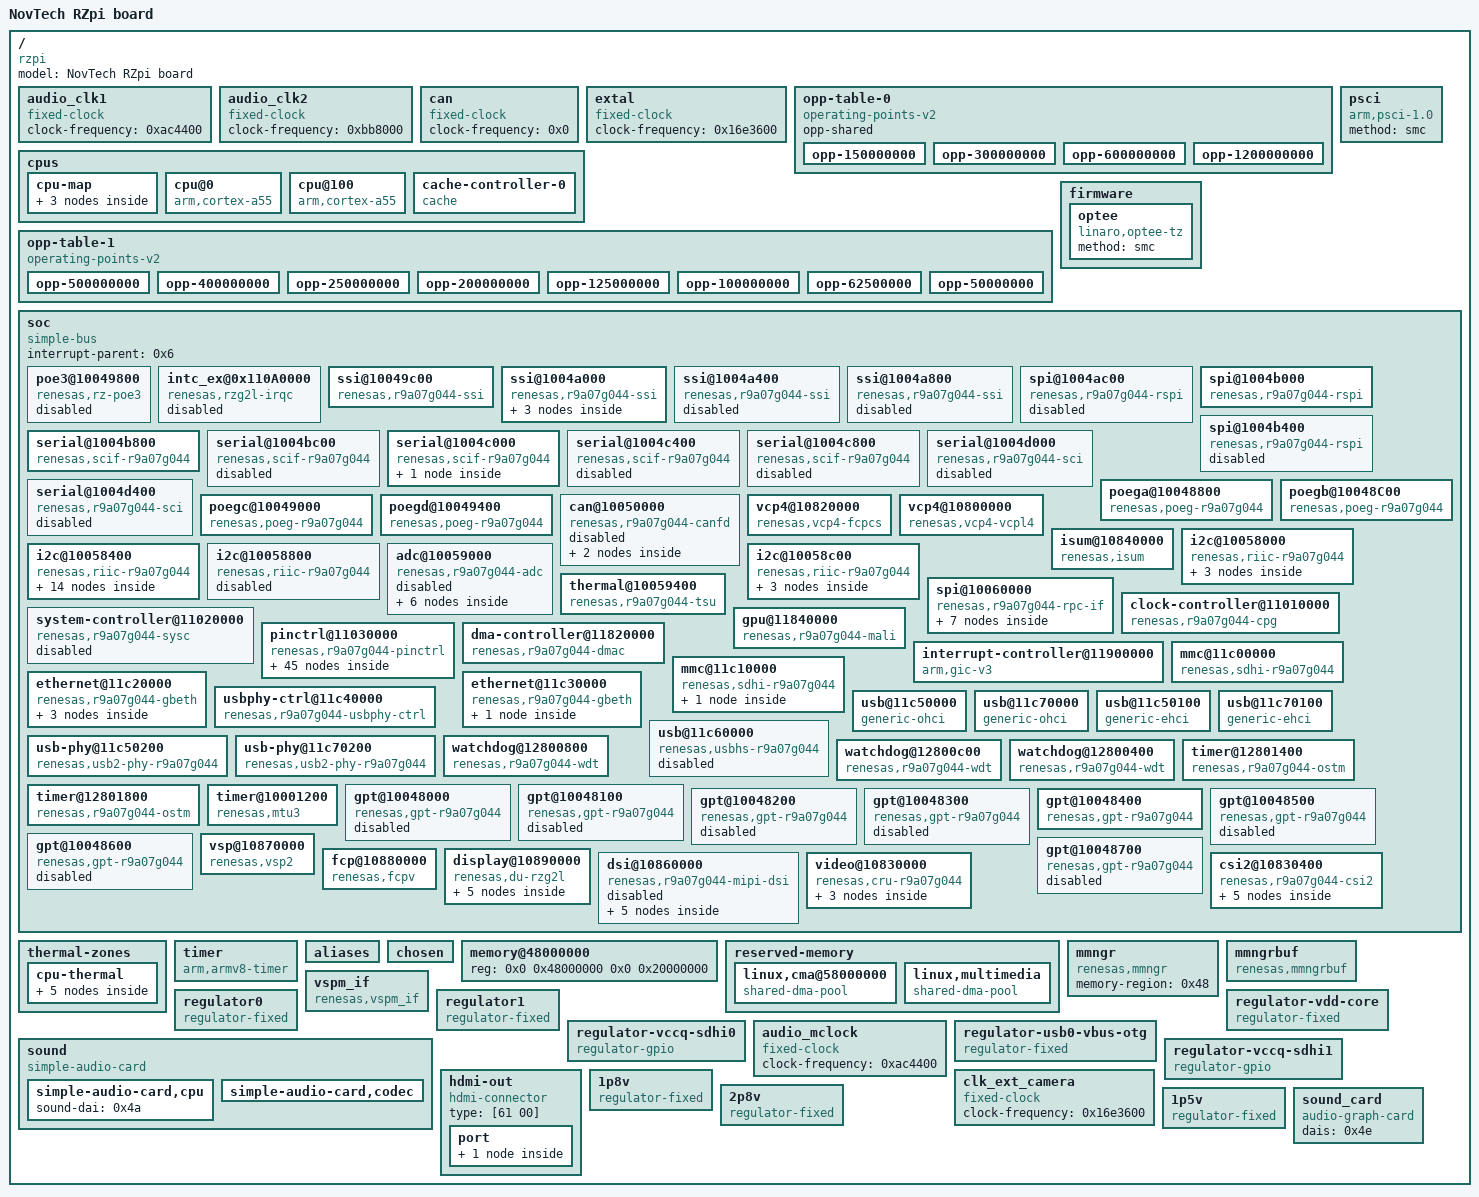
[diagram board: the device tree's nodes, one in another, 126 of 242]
/dts-v1/;

/ {
	compatible = "rzpi", "renesas,r9a07g044l2", "renesas,r9a07g044";
	#address-cells = <0x2>;
	#size-cells = <0x2>;
	model = "NovTech RZpi board";

	audio_clk1 {
		compatible = "fixed-clock";
		#clock-cells = <0x0>;
		clock-frequency = <0xac4400>;
		phandle = <0x7>;
	};

	audio_clk2 {
		compatible = "fixed-clock";
		#clock-cells = <0x0>;
		clock-frequency = <0xbb8000>;
		phandle = <0x8>;
	};

	can {
		compatible = "fixed-clock";
		#clock-cells = <0x0>;
		clock-frequency = <0x0>;
		phandle = <0x11>;
	};

	extal {
		compatible = "fixed-clock";
		#clock-cells = <0x0>;
		clock-frequency = <0x16e3600>;
		phandle = <0x24>;
	};

	opp-table-0 {
		compatible = "operating-points-v2";
		opp-shared;
		phandle = <0x5>;

		opp-150000000 {
			opp-hz = <0x0 0x8f0d180>;
			opp-microvolt = <0x10c8e0>;
			clock-latency-ns = <0x493e0>;
		};

		opp-300000000 {
			opp-hz = <0x0 0x11e1a300>;
			opp-microvolt = <0x10c8e0>;
			clock-latency-ns = <0x493e0>;
		};

		opp-600000000 {
			opp-hz = <0x0 0x23c34600>;
			opp-microvolt = <0x10c8e0>;
			clock-latency-ns = <0x493e0>;
		};

		opp-1200000000 {
			opp-hz = <0x0 0x47868c00>;
			opp-microvolt = <0x10c8e0>;
			clock-latency-ns = <0x493e0>;
			opp-suspend;
		};
	};

	cpus {
		#address-cells = <0x1>;
		#size-cells = <0x0>;

		cpu-map {

			cluster0 {

				core0 {
					cpu = <0x1>;
				};

				core1 {
					cpu = <0x2>;
				};
			};
		};

		cpu@0 {
			compatible = "arm,cortex-a55";
			reg = <0x0>;
			device_type = "cpu";
			#cooling-cells = <0x2>;
			next-level-cache = <0x3>;
			enable-method = "psci";
			clocks = <0x4 0x0 0x0>;
			operating-points-v2 = <0x5>;
			phandle = <0x1>;
		};

		cpu@100 {
			compatible = "arm,cortex-a55";
			reg = <0x100>;
			device_type = "cpu";
			next-level-cache = <0x3>;
			enable-method = "psci";
			clocks = <0x4 0x0 0x0>;
			operating-points-v2 = <0x5>;
			phandle = <0x2>;
		};

		cache-controller-0 {
			compatible = "cache";
			cache-unified;
			cache-size = <0x40000>;
			phandle = <0x3>;
		};
	};

	opp-table-1 {
		compatible = "operating-points-v2";
		phandle = <0x26>;

		opp-500000000 {
			opp-hz = <0x0 0x1dcd6500>;
			opp-microvolt = <0x10c8e0>;
		};

		opp-400000000 {
			opp-hz = <0x0 0x17d78400>;
			opp-microvolt = <0x10c8e0>;
		};

		opp-250000000 {
			opp-hz = <0x0 0xee6b280>;
			opp-microvolt = <0x10c8e0>;
		};

		opp-200000000 {
			opp-hz = <0x0 0xbebc200>;
			opp-microvolt = <0x10c8e0>;
		};

		opp-125000000 {
			opp-hz = <0x0 0x7735940>;
			opp-microvolt = <0x10c8e0>;
		};

		opp-100000000 {
			opp-hz = <0x0 0x5f5e100>;
			opp-microvolt = <0x10c8e0>;
		};

		opp-62500000 {
			opp-hz = <0x0 0x3b9aca0>;
			opp-microvolt = <0x10c8e0>;
		};

		opp-50000000 {
			opp-hz = <0x0 0x2faf080>;
			opp-microvolt = <0x10c8e0>;
		};
	};

	psci {
		compatible = "arm,psci-1.0", "arm,psci-0.2";
		method = "smc";
	};

	firmware {

		optee {
			compatible = "linaro,optee-tz";
			method = "smc";
		};
	};

	soc {
		compatible = "simple-bus";
		interrupt-parent = <0x6>;
		#address-cells = <0x2>;
		#size-cells = <0x2>;
		ranges;

		poe3@10049800 {
			compatible = "renesas,rz-poe3", "renesas,r9a07g044-poe3";
			reg = <0x0 0x10049800 0x0 0x18>;
			interrupts = <0x0 0xd6 0x4 0x0 0xd7 0x4 0x0 0xd8 0x4 0x0 0xd9 0x4>;
			interrupt-names = "oei1", "oei2", "oei3", "oei4";
			clocks = <0x4 0x1 0x12>;
			clock-names = "fck";
			resets = <0x4 0x18>;
			power-domains = <0x4>;
			status = "disabled";
		};

		intc_ex@0x110A0000 {
			compatible = "renesas,rzg2l-irqc";
			#interrupt-cells = <0x2>;
			interrupt-controller;
			reg = <0x0 0x110a0000 0x0 0x10000>;
			interrupts = <0x0 0x1 0x4 0x0 0x2 0x4 0x0 0x3 0x4 0x0 0x4 0x4 0x0 0x5 0x4 0x0 0x6 0x4 0x0 0x7 0x4 0x0 0x8 0x4 0x0 0x0 0x4>;
			interrupt-names = "irq0", "irq1", "irq2", "irq3", "irq4", "irq5", "irq6", "irq7", "nmi";
			clocks = <0x4 0x1 0x8>;
			resets = <0x4 0xf>;
			power-domains = <0x4>;
			status = "disabled";
		};

		ssi@10049c00 {
			compatible = "renesas,r9a07g044-ssi", "renesas,rz-ssi";
			reg = <0x0 0x10049c00 0x0 0x400>;
			interrupts = <0x0 0x146 0x4 0x0 0x147 0x1 0x0 0x148 0x1 0x0 0x149 0x1>;
			interrupt-names = "int_req", "dma_rx", "dma_tx", "dma_rt";
			clocks = <0x4 0x1 0x3c 0x4 0x1 0x3d 0x7 0x8>;
			clock-names = "ssi", "ssi_sfr", "audio_clk1", "audio_clk2";
			resets = <0x4 0x32>;
			dmas = <0x9 0x2655 0x9 0x2656>;
			dma-names = "tx", "rx";
			power-domains = <0x4>;
			#sound-dai-cells = <0x0>;
			status = "okay";
			pinctrl-0 = <0xa>;
			pinctrl-names = "default";
			phandle = <0x4a>;
		};

		ssi@1004a000 {
			compatible = "renesas,r9a07g044-ssi", "renesas,rz-ssi";
			reg = <0x0 0x1004a000 0x0 0x400>;
			interrupts = <0x0 0x14a 0x4 0x0 0x14b 0x1 0x0 0x14c 0x1 0x0 0x14d 0x1>;
			interrupt-names = "int_req", "dma_rx", "dma_tx", "dma_rt";
			clocks = <0x4 0x1 0x3e 0x4 0x1 0x3f 0x7 0x8>;
			clock-names = "ssi", "ssi_sfr", "audio_clk1", "audio_clk2";
			resets = <0x4 0x33>;
			dmas = <0x9 0x2659 0x9 0x265a>;
			dma-names = "tx", "rx";
			power-domains = <0x4>;
			#sound-dai-cells = <0x0>;
			status = "okay";
			pinctrl-0 = <0xb>;
			pinctrl-names = "default";

			ports {

				port@0 {
					phandle = <0x4e>;

					endpoint {
						remote-endpoint = <0xc>;
						dai-format = "i2s";
						phandle = <0x1f>;
					};
				};
			};
		};

		ssi@1004a400 {
			compatible = "renesas,r9a07g044-ssi", "renesas,rz-ssi";
			reg = <0x0 0x1004a400 0x0 0x400>;
			interrupts = <0x0 0x14e 0x4 0x0 0x14f 0x1 0x0 0x150 0x1 0x0 0x151 0x1>;
			interrupt-names = "int_req", "dma_rx", "dma_tx", "dma_rt";
			clocks = <0x4 0x1 0x40 0x4 0x1 0x41 0x7 0x8>;
			clock-names = "ssi", "ssi_sfr", "audio_clk1", "audio_clk2";
			resets = <0x4 0x34>;
			dmas = <0x9 0x265f>;
			dma-names = "rt";
			power-domains = <0x4>;
			#sound-dai-cells = <0x0>;
			status = "disabled";
		};

		ssi@1004a800 {
			compatible = "renesas,r9a07g044-ssi", "renesas,rz-ssi";
			reg = <0x0 0x1004a800 0x0 0x400>;
			interrupts = <0x0 0x152 0x4 0x0 0x153 0x1 0x0 0x154 0x1 0x0 0x155 0x1>;
			interrupt-names = "int_req", "dma_rx", "dma_tx", "dma_rt";
			clocks = <0x4 0x1 0x42 0x4 0x1 0x43 0x7 0x8>;
			clock-names = "ssi", "ssi_sfr", "audio_clk1", "audio_clk2";
			resets = <0x4 0x35>;
			dmas = <0x9 0x2661 0x9 0x2662>;
			dma-names = "tx", "rx";
			power-domains = <0x4>;
			#sound-dai-cells = <0x0>;
			status = "disabled";
		};

		spi@1004ac00 {
			compatible = "renesas,r9a07g044-rspi", "renesas,rspi-rz";
			reg = <0x0 0x1004ac00 0x0 0x400>;
			interrupts = <0x0 0x19f 0x4 0x0 0x19d 0x4 0x0 0x19e 0x4>;
			interrupt-names = "error", "rx", "tx";
			clocks = <0x4 0x1 0x59>;
			resets = <0x4 0x49>;
			power-domains = <0x4>;
			num-cs = <0x1>;
			#address-cells = <0x1>;
			#size-cells = <0x0>;
			status = "disabled";
		};

		spi@1004b000 {
			compatible = "renesas,r9a07g044-rspi", "renesas,rspi-rz";
			reg = <0x0 0x1004b000 0x0 0x400>;
			interrupts = <0x0 0x1a2 0x4 0x0 0x1a0 0x4 0x0 0x1a1 0x4>;
			interrupt-names = "error", "rx", "tx";
			clocks = <0x4 0x1 0x5a>;
			resets = <0x4 0x4a>;
			power-domains = <0x4>;
			num-cs = <0x1>;
			#address-cells = <0x1>;
			#size-cells = <0x0>;
			status = "okay";
			pinctrl-0 = <0xd>;
			pinctrl-names = "default";
			dmas = <0x9 0x2e99 0x9 0x2e9a>;
			dma-names = "tx", "rx";
		};

		spi@1004b400 {
			compatible = "renesas,r9a07g044-rspi", "renesas,rspi-rz";
			reg = <0x0 0x1004b400 0x0 0x400>;
			interrupts = <0x0 0x1a5 0x4 0x0 0x1a3 0x4 0x0 0x1a4 0x4>;
			interrupt-names = "error", "rx", "tx";
			clocks = <0x4 0x1 0x5b>;
			resets = <0x4 0x4b>;
			power-domains = <0x4>;
			num-cs = <0x1>;
			#address-cells = <0x1>;
			#size-cells = <0x0>;
			status = "disabled";
		};

		serial@1004b800 {
			compatible = "renesas,scif-r9a07g044";
			reg = <0x0 0x1004b800 0x0 0x400>;
			interrupts = <0x0 0x17c 0x4 0x0 0x17e 0x4 0x0 0x17f 0x4 0x0 0x17d 0x4 0x0 0x180 0x4 0x0 0x180 0x4>;
			interrupt-names = "eri", "rxi", "txi", "bri", "dri", "tei";
			clocks = <0x4 0x1 0x51>;
			clock-names = "fck";
			power-domains = <0x4>;
			resets = <0x4 0x41>;
			status = "okay";
			pinctrl-0 = <0xe>;
			pinctrl-names = "default";
		};

		serial@1004bc00 {
			compatible = "renesas,scif-r9a07g044";
			reg = <0x0 0x1004bc00 0x0 0x400>;
			interrupts = <0x0 0x181 0x4 0x0 0x183 0x4 0x0 0x184 0x4 0x0 0x182 0x4 0x0 0x185 0x4 0x0 0x185 0x4>;
			interrupt-names = "eri", "rxi", "txi", "bri", "dri", "tei";
			clocks = <0x4 0x1 0x52>;
			clock-names = "fck";
			power-domains = <0x4>;
			resets = <0x4 0x42>;
			status = "disabled";
		};

		serial@1004c000 {
			compatible = "renesas,scif-r9a07g044";
			reg = <0x0 0x1004c000 0x0 0x400>;
			interrupts = <0x0 0x186 0x4 0x0 0x188 0x4 0x0 0x189 0x4 0x0 0x187 0x4 0x0 0x18a 0x4 0x0 0x18a 0x4>;
			interrupt-names = "eri", "rxi", "txi", "bri", "dri", "tei";
			clocks = <0x4 0x1 0x53>;
			clock-names = "fck";
			power-domains = <0x4>;
			resets = <0x4 0x43>;
			status = "okay";
			pinctrl-names = "default";
			pinctrl-0 = <0xf>;
			uart-has-rtscts;

			bluetooth {
				compatible = "brcm,bcm43438-bt";
				device-wakeup-gpios = <0x10 0x128 0x1>;
				host-wakeup-gpios = <0x10 0x129 0x1>;
				status = "okay";
			};
		};

		serial@1004c400 {
			compatible = "renesas,scif-r9a07g044";
			reg = <0x0 0x1004c400 0x0 0x400>;
			interrupts = <0x0 0x18b 0x4 0x0 0x18d 0x4 0x0 0x18e 0x4 0x0 0x18c 0x4 0x0 0x18f 0x4 0x0 0x18f 0x4>;
			interrupt-names = "eri", "rxi", "txi", "bri", "dri", "tei";
			clocks = <0x4 0x1 0x54>;
			clock-names = "fck";
			power-domains = <0x4>;
			resets = <0x4 0x44>;
			status = "disabled";
		};

		serial@1004c800 {
			compatible = "renesas,scif-r9a07g044";
			reg = <0x0 0x1004c800 0x0 0x400>;
			interrupts = <0x0 0x190 0x4 0x0 0x192 0x4 0x0 0x193 0x4 0x0 0x191 0x4 0x0 0x194 0x4 0x0 0x194 0x4>;
			interrupt-names = "eri", "rxi", "txi", "bri", "dri", "tei";
			clocks = <0x4 0x1 0x55>;
			clock-names = "fck";
			power-domains = <0x4>;
			resets = <0x4 0x45>;
			status = "disabled";
		};

		serial@1004d000 {
			compatible = "renesas,r9a07g044-sci", "renesas,sci";
			reg = <0x0 0x1004d000 0x0 0x400>;
			interrupts = <0x0 0x195 0x4 0x0 0x196 0x4 0x0 0x197 0x4 0x0 0x198 0x4>;
			interrupt-names = "eri", "rxi", "txi", "tei";
			clocks = <0x4 0x1 0x56>;
			clock-names = "fck";
			power-domains = <0x4>;
			resets = <0x4 0x46>;
			status = "disabled";
		};

		serial@1004d400 {
			compatible = "renesas,r9a07g044-sci", "renesas,sci";
			reg = <0x0 0x1004d400 0x0 0x400>;
			interrupts = <0x0 0x199 0x4 0x0 0x19a 0x4 0x0 0x19b 0x4 0x0 0x19c 0x4>;
			interrupt-names = "eri", "rxi", "txi", "tei";
			clocks = <0x4 0x1 0x57>;
			clock-names = "fck";
			power-domains = <0x4>;
			resets = <0x4 0x47>;
			status = "disabled";
		};

		poega@10048800 {
			compatible = "renesas,poeg-r9a07g044";
			reg = <0x0 0x10048800 0x0 0x4>;
			interrupts = <0x0 0x142 0x4>;
			clocks = <0x4 0x1 0x14>;
			power-domains = <0x4>;
			resets = <0x4 0x1a>;
			status = "okay";
			phandle = <0x38>;
		};

		poegb@10048C00 {
			compatible = "renesas,poeg-r9a07g044";
			reg = <0x0 0x10048c00 0x0 0x4>;
			interrupts = <0x0 0x143 0x4>;
			clocks = <0x4 0x1 0x15>;
			power-domains = <0x4>;
			resets = <0x4 0x1b>;
			status = "okay";
			phandle = <0x39>;
		};

		poegc@10049000 {
			compatible = "renesas,poeg-r9a07g044";
			reg = <0x0 0x10049000 0x0 0x4>;
			interrupts = <0x0 0x144 0x4>;
			clocks = <0x4 0x1 0x16>;
			power-domains = <0x4>;
			resets = <0x4 0x1c>;
			status = "okay";
			phandle = <0x3a>;
		};

		poegd@10049400 {
			compatible = "renesas,poeg-r9a07g044";
			reg = <0x0 0x10049400 0x0 0x4>;
			interrupts = <0x0 0x145 0x4>;
			clocks = <0x4 0x1 0x17>;
			power-domains = <0x4>;
			resets = <0x4 0x1d>;
			status = "okay";
			phandle = <0x3b>;
		};

		can@10050000 {
			compatible = "renesas,r9a07g044-canfd", "renesas,rzg2l-canfd";
			reg = <0x0 0x10050000 0x0 0x8000>;
			interrupts = <0x0 0x1aa 0x4 0x0 0x1ab 0x4 0x0 0x1a6 0x4 0x0 0x1a8 0x4 0x0 0x1ac 0x4 0x0 0x1a7 0x4 0x0 0x1a9 0x4 0x0 0x1ad 0x4>;
			interrupt-names = "g_err", "g_recc", "ch0_err", "ch0_rec", "ch0_trx", "ch1_err", "ch1_rec", "ch1_trx";
			clocks = <0x4 0x1 0x5c 0x4 0x0 0x16 0x11>;
			clock-names = "fck", "canfd", "can_clk";
			assigned-clocks = <0x4 0x0 0x16>;
			assigned-clock-rates = <0x2faf080>;
			resets = <0x4 0x4c 0x4 0x4d>;
			reset-names = "rstp_n", "rstc_n";
			power-domains = <0x4>;
			status = "disabled";
			pinctrl-0 = <0x12 0x13>;
			pinctrl-names = "default";

			channel0 {
				status = "okay";
			};

			channel1 {
				status = "okay";
			};
		};

		vcp4@10820000 {
			compatible = "renesas,vcp4-fcpcs";
			reg = <0x0 0x10820000 0x0 0x200>;
			renesas,#ch = <0x0>;
		};

		vcp4@10800000 {
			compatible = "renesas,vcp4-vcpl4";
			reg = <0x0 0x10800000 0x0 0x200 0x0 0x10810200 0x0 0x200>;
			interrupts = <0x0 0xa1 0x4 0x0 0xa2 0x4>;
			clocks = <0x4 0x1 0x2d 0x4 0x1 0x2e>;
			power-domains = <0x4>;
			resets = <0x4 0x29 0x4 0x2a>;
			renesas,#ch = <0x0>;
			renesas,#fcp_ch = <0x0>;
		};

		isum@10840000 {
			compatible = "renesas,isum";
			reg = <0x0 0x10840000 0x0 0x1f4>;
			interrupts = <0x0 0x9d 0x4 0x0 0x9e 0x4 0x0 0x9f 0x4 0x0 0xa0 0x4>;
			clocks = <0x4 0x1 0x2b 0x4 0x1 0x2c>;
			clock-names = "isu_aclk", "isu_pclk";
			resets = <0x4 0x27 0x4 0x28>;
			reset-names = "aresetn", "presetn";
			renesas,#ch = <0x0>;
			renesas,#rpf = <0x1>;
			renesas,#wpf = <0x1>;
			renesas,has-rs;
			power-domains = <0x4>;
		};

		i2c@10058000 {
			#address-cells = <0x1>;
			#size-cells = <0x0>;
			compatible = "renesas,riic-r9a07g044", "renesas,riic-rz";
			reg = <0x0 0x10058000 0x0 0x400>;
			interrupts = <0x0 0x15e 0x4 0x0 0x15c 0x1 0x0 0x15d 0x1 0x0 0x160 0x4 0x0 0x161 0x4 0x0 0x15f 0x4 0x0 0x162 0x4 0x0 0x163 0x4>;
			interrupt-names = "tei", "ri", "ti", "spi", "sti", "naki", "ali", "tmoi";
			clocks = <0x4 0x1 0x4d>;
			clock-frequency = <0x186a0>;
			resets = <0x4 0x3d>;
			power-domains = <0x4>;
			status = "okay";
			pinctrl-0 = <0x14>;
			pinctrl-names = "default";

			camera@3c {
				compatible = "ovti,ov5645";
				reg = <0x3c>;
				clock-names = "xclk";
				clocks = <0x15>;
				clock-frequency = <0x16e3600>;
				vdddo-supply = <0x16>;
				vdda-supply = <0x17>;
				vddd-supply = <0x18>;
				enable-gpios = <0x10 0x10 0x0>;
				reset-gpios = <0x10 0x142 0x1>;

				port {

					endpoint {
						clock-lanes = <0x0>;
						data-lanes = <0x1 0x2>;
						remote-endpoint = <0x19>;
						phandle = <0x45>;
					};
				};
			};
		};

		i2c@10058400 {
			#address-cells = <0x1>;
			#size-cells = <0x0>;
			compatible = "renesas,riic-r9a07g044", "renesas,riic-rz";
			reg = <0x0 0x10058400 0x0 0x400>;
			interrupts = <0x0 0x166 0x4 0x0 0x164 0x1 0x0 0x165 0x1 0x0 0x168 0x4 0x0 0x169 0x4 0x0 0x167 0x4 0x0 0x16a 0x4 0x0 0x16b 0x4>;
			interrupt-names = "tei", "ri", "ti", "spi", "sti", "naki", "ali", "tmoi";
			clocks = <0x4 0x1 0x4e>;
			clock-frequency = <0x186a0>;
			resets = <0x4 0x3e>;
			power-domains = <0x4>;
			status = "okay";
			pinctrl-0 = <0x1a>;
			pinctrl-names = "default";

			hdmi@3d {
				compatible = "adi,adv7535";
				reg = <0x3d>;
				avdd-supply = <0x1b>;
				dvdd-supply = <0x1b>;
				pvdd-supply = <0x1b>;
				a2vdd-supply = <0x1b>;
				v3p3-supply = <0x1c>;
				v1p2-supply = <0x1b>;
				adi,dsi-lanes = <0x4>;
				#sound-dai-cells = <0x0>;
				interrupt-parent = <0x10>;
				interrupts = <0x11 0x2>;
				status = "disabled";

				ports {
					#address-cells = <0x1>;
					#size-cells = <0x0>;

					port@0 {
						reg = <0x0>;

						endpoint@0 {
							remote-endpoint = <0x1d>;
							phandle = <0x42>;
						};
					};

					port@1 {
						reg = <0x1>;

						endpoint@1 {
							remote-endpoint = <0x1e>;
						};
					};

					port@2 {
						reg = <0x2>;

						endpoint {
							remote-endpoint = <0x1f>;
							phandle = <0xc>;
						};
					};
				};
			};

			hdmi@39 {
				#sound-dai-cells = <0x0>;
				compatible = "sil,sii9022";
				reg = <0x39>;
				status = "okay";

				ports {
					#address-cells = <0x1>;
					#size-cells = <0x0>;

					port@0 {
						reg = <0x0>;

						endpoint {
							remote-endpoint = <0x20>;
							phandle = <0x3f>;
						};
					};

					port@1 {
						reg = <0x1>;

						endpoint {
							remote-endpoint = <0x1e>;
							phandle = <0x4d>;
						};
					};
				};
			};
		};

		i2c@10058800 {
			#address-cells = <0x1>;
			#size-cells = <0x0>;
			compatible = "renesas,riic-r9a07g044", "renesas,riic-rz";
			reg = <0x0 0x10058800 0x0 0x400>;
			interrupts = <0x0 0x16e 0x4 0x0 0x16c 0x1 0x0 0x16d 0x1 0x0 0x170 0x4 0x0 0x171 0x4 0x0 0x16f 0x4 0x0 0x172 0x4 0x0 0x173 0x4>;
			interrupt-names = "tei", "ri", "ti", "spi", "sti", "naki", "ali", "tmoi";
			clocks = <0x4 0x1 0x4f>;
			clock-frequency = <0x186a0>;
			resets = <0x4 0x3f>;
			power-domains = <0x4>;
			status = "disabled";
		};

		i2c@10058c00 {
			#address-cells = <0x1>;
			#size-cells = <0x0>;
			compatible = "renesas,riic-r9a07g044", "renesas,riic-rz";
			reg = <0x0 0x10058c00 0x0 0x400>;
			interrupts = <0x0 0x176 0x4 0x0 0x174 0x1 0x0 0x175 0x1 0x0 0x178 0x4 0x0 0x179 0x4 0x0 0x177 0x4 0x0 0x17a 0x4 0x0 0x17b 0x4>;
			interrupt-names = "tei", "ri", "ti", "spi", "sti", "naki", "ali", "tmoi";
			clocks = <0x4 0x1 0x50>;
			clock-frequency = <0x61a80>;
			resets = <0x4 0x40>;
			power-domains = <0x4>;
			status = "okay";
			pinctrl-0 = <0x21>;
			pinctrl-names = "default";

			raa215300@12 {
				compatible = "renesas,raa215300";
				reg = <0x12>;
				rtc-enable;
			};

			isl1208@6f {
				compatible = "isil,isl1208";
				reg = <0x6f>;
				external-oscillator;
			};

			codec@1a {
				compatible = "wlf,wm8978";
				#sound-dai-cells = <0x0>;
				reg = <0x1a>;
				phandle = <0x4c>;
			};
		};

		adc@10059000 {
			compatible = "renesas,r9a07g044-adc", "renesas,rzg2l-adc";
			reg = <0x0 0x10059000 0x0 0x400>;
			interrupts = <0x0 0x15b 0x1>;
			clocks = <0x4 0x1 0x5e 0x4 0x1 0x5f>;
			clock-names = "adclk", "pclk";
			resets = <0x4 0x51 0x4 0x52>;
			reset-names = "presetn", "adrst-n";
			power-domains = <0x4>;
			status = "disabled";
			#address-cells = <0x1>;
			#size-cells = <0x0>;
			pinctrl-0 = <0x22>;
			pinctrl-names = "default";

			channel@0 {
				reg = <0x0>;
			};

			channel@1 {
				reg = <0x1>;
			};

			channel@2 {
				reg = <0x2>;
			};

			channel@3 {
				reg = <0x3>;
			};

			channel@4 {
				reg = <0x4>;
			};

			channel@5 {
				reg = <0x5>;
			};
		};

		thermal@10059400 {
			compatible = "renesas,r9a07g044-tsu", "renesas,rzg2l-tsu";
			reg = <0x0 0x10059400 0x0 0x400>;
			clocks = <0x4 0x1 0x60>;
			resets = <0x4 0x53>;
			power-domains = <0x4>;
			#thermal-sensor-cells = <0x1>;
			phandle = <0x46>;
		};

		spi@10060000 {
			compatible = "renesas,r9a07g044-rpc-if", "renesas,rzg2l-rpc-if";
			reg = <0x0 0x10060000 0x0 0x10000 0x0 0x20000000 0x0 0x10000000 0x0 0x10070000 0x0 0x10000>;
			reg-names = "regs", "dirmap", "wbuf";
			interrupts = <0x0 0x29 0x4>;
			clocks = <0x4 0x1 0x1e 0x4 0x1 0x1f>;
			resets = <0x4 0x21>;
			power-domains = <0x4>;
			#address-cells = <0x1>;
			#size-cells = <0x0>;
			status = "okay";
			pinctrl-0 = <0x23>;
			pinctrl-names = "default";

			flash@0 {
				compatible = "micron,mt25qu512a", "jedec,spi-nor";
				reg = <0x0>;
				m25p,fast-read;
				spi-max-frequency = <0x2faf080>;
				spi-rx-bus-width = <0x4>;
				spi-tx-bus-width = <0x4>;

				partitions {
					compatible = "fixed-partitions";
					#address-cells = <0x1>;
					#size-cells = <0x1>;

					partition@0000000 {
						label = "u-boot";
						reg = <0x0 0x80000>;
						read-only;
					};

					partition@80000 {
						label = "env";
						reg = <0x80000 0x40000>;
						read-only;
					};

					partition@C0000 {
						label = "dtb";
						reg = <0xc0000 0x40000>;
						read-only;
					};

					partition@800000 {
						label = "rootfs";
						reg = <0x800000 0x1000000>;
					};

					partition@2000000 {
						label = "test-area";
						reg = <0x2000000 0x100000>;
					};
				};
			};
		};

		clock-controller@11010000 {
			compatible = "renesas,r9a07g044-cpg";
			reg = <0x0 0x11010000 0x0 0x10000>;
			clocks = <0x24>;
			clock-names = "extal";
			#clock-cells = <0x2>;
			#reset-cells = <0x1>;
			#power-domain-cells = <0x0>;
			phandle = <0x4>;
		};

		system-controller@11020000 {
			compatible = "renesas,r9a07g044-sysc";
			reg = <0x0 0x11020000 0x0 0x10000>;
			interrupts = <0x0 0x2a 0x4 0x0 0x2b 0x4 0x0 0x2c 0x4 0x0 0x2d 0x4>;
			interrupt-names = "lpm_int", "ca55stbydone_int", "cm33stbyr_int", "ca55_deny";
			status = "disabled";
		};

		pinctrl@11030000 {
			compatible = "renesas,r9a07g044-pinctrl";
			reg = <0x0 0x11030000 0x0 0x10000 0x0 0x110a0020 0x0 0x30>;
			gpio-controller;
			#gpio-cells = <0x2>;
			gpio-ranges = <0x10 0x0 0x0 0x188>;
			clocks = <0x4 0x1 0x5d>;
			power-domains = <0x4>;
			resets = <0x4 0x4e 0x4 0x4f 0x4 0x50>;
			interrupt-controller;
			#interrupt-cells = <0x2>;
			interrupts = <0x0 0x1bc 0x4 0x0 0x1bd 0x4 0x0 0x1be 0x4 0x0 0x1bf 0x4 0x0 0x1c0 0x4 0x0 0x1c1 0x4 0x0 0x1c2 0x4 0x0 0x1c3 0x4 0x0 0x1c4 0x4 0x0 0x1c5 0x4 0x0 0x1c6 0x4 0x0 0x1c7 0x4 0x0 0x1c8 0x4 0x0 0x1c9 0x4 0x0 0x1ca 0x4 0x0 0x1cb 0x4 0x0 0x1cc 0x4 0x0 0x1cd 0x4 0x0 0x1ce 0x4 0x0 0x1cf 0x4 0x0 0x1d0 0x4 0x0 0x1d1 0x4 0x0 0x1d2 0x4 0x0 0x1d3 0x4 0x0 0x1d4 0x4 0x0 0x1d5 0x4 0x0 0x1d6 0x4 0x0 0x1d7 0x4 0x0 0x1d8 0x4 0x0 0x1d9 0x4 0x0 0x1da 0x4 0x0 0x1db 0x4>;
			pinctrl-0 = <0x25>;
			pinctrl-names = "default";
			phandle = <0x10>;

			adc {
				pinmux = <0x20048>;
				phandle = <0x22>;
			};

			eth0 {
				pinmux = <0x100e1 0x100d9 0x100e0 0x100a0 0x100a1 0x100a2 0x100a8 0x100a9 0x100b0 0x100c0 0x100c1 0x100c8 0x100c9 0x100d0 0x100d1>;
				phandle = <0x2c>;
			};

			eth1 {
				pinmux = <0x100e8 0x100e9 0x100f0 0x100f1 0x100f8 0x100f9 0x10109 0x10110 0x10111 0x10118 0x10119 0x10120>;
				phandle = <0x2e>;
			};

			gpio-sd0-pwr-en-hog {
				gpio-hog;
				gpios = <0x21 0x0>;
				output-high;
				line-name = "gpio_sd0_pwr_en";
			};

			qspi0 {
				phandle = <0x23>;

				qspi0-data {
					pins = "QSPI0_IO0", "QSPI0_IO1", "QSPI0_IO2", "QSPI0_IO3";
					power-source = <0x708>;
				};

				qspi0-ctrl {
					pins = "QSPI0_SPCLK", "QSPI0_SSL", "QSPI_RESET#";
					power-source = <0x708>;
				};
			};

			sd0-dev-sel-hog {
				gpio-hog;
				gpios = <0x149 0x0>;
				output-high;
				line-name = "sd0_dev_sel";
			};

			sd0emmc {
				phandle = <0x28>;

				sd0_emmc_data {
					pins = "SD0_DATA0", "SD0_DATA1", "SD0_DATA2", "SD0_DATA3", "SD0_DATA4", "SD0_DATA5", "SD0_DATA6", "SD0_DATA7";
					power-source = <0x708>;
				};

				sd0_emmc_ctrl {
					pins = "SD0_CLK", "SD0_CMD";
					power-source = <0x708>;
				};

				sd0_emmc_rst {
					pins = "SD0_RST#";
					power-source = <0x708>;
				};
			};

			sd0 {

				sd0_data {
					pins = "SD0_DATA0", "SD0_DATA1", "SD0_DATA2", "SD0_DATA3";
					power-source = <0xce4>;
				};

				sd0_ctrl {
					pins = "SD0_CLK", "SD0_CMD";
					power-source = <0xce4>;
				};

				sd0_mux {
					pinmux = <0x20178>;
				};
			};

			sd0_uhs {

				sd0_data_uhs {
					pins = "SD0_DATA0", "SD0_DATA1", "SD0_DATA2", "SD0_DATA3";
					power-source = <0x708>;
				};

				sd0_ctrl_uhs {
					pins = "SD0_CLK", "SD0_CMD";
					power-source = <0x708>;
				};

				sd0_mux_uhs {
					pinmux = <0x20178>;
				};
			};

			can0 {
				pinmux = <0x20051 0x20058>;
				phandle = <0x12>;
			};

			can0-stb {
				gpio-hog;
				gpios = <0x152 0x0>;
				output-low;
				line-name = "can0_stb";
			};

			can1 {
				pinmux = <0x20061 0x20068>;
				phandle = <0x13>;
			};

			i2c0 {
				pins = "RIIC0_SDA", "RIIC0_SCL";
				input-enable;
				phandle = <0x14>;
			};

			i2c1 {
				pins = "RIIC1_SDA", "RIIC1_SCL";
				input-enable;
				phandle = <0x1a>;
			};

			i2c3 {
				pinmux = <0x30090 0x30091>;
				phandle = <0x21>;
			};

			scif0 {
				pinmux = <0x10130 0x10131>;
				phandle = <0xe>;
			};

			scif2 {
				pinmux = <0x10180 0x10181 0x40153 0x40154>;
				phandle = <0xf>;
			};

			sd1-pwr-en-hog {
				gpio-hog;
				gpios = <0x13a 0x0>;
				output-high;
				line-name = "sd1_pwr_en";
			};

			sd1 {
				phandle = <0x29>;

				sd1_data {
					pins = "SD1_DATA0", "SD1_DATA1", "SD1_DATA2", "SD1_DATA3";
					power-source = <0xce4>;
				};

				sd1_ctrl {
					pins = "SD1_CLK", "SD1_CMD";
					power-source = <0xce4>;
				};

				sd1_mux {
					pinmux = <0x10098>;
				};
			};

			sd1_uhs {
				phandle = <0x2a>;

				sd1_data_uhs {
					pins = "SD1_DATA0", "SD1_DATA1", "SD1_DATA2", "SD1_DATA3";
					power-source = <0x708>;
				};

				sd1_ctrl_uhs {
					pins = "SD1_CLK", "SD1_CMD";
					power-source = <0x708>;
				};

				sd1_mux_uhs {
					pinmux = <0x10098>;
				};
			};

			sound_clk {
				pins = "AUDIO_CLK1", "AUDIO_CLK2";
				input-enable;
				phandle = <0x25>;
			};

			spi1 {
				pinmux = <0x10160 0x10161 0x10162 0x10163>;
				phandle = <0xd>;
			};

			ssi0 {
				pinmux = <0x10168 0x10169 0x1016a 0x1016b>;
				phandle = <0xa>;
			};

			ssi1 {
				pinmux = <0x10170 0x10171 0x10172 0x10173>;
				phandle = <0xb>;
			};

			usb0 {
				pinmux = <0x10020 0x10028 0x10029>;
			};

			usb1 {
				pinmux = <0x10150 0x10151>;
				phandle = <0x36>;
			};

			gpt4 {
				pinmux = <0x20158 0x20159>;
				phandle = <0x37>;
			};

			du {
				pinmux = <0x10030 0x10031 0x10038 0x10039 0x10041 0x10042 0x10048 0x10049 0x10050 0x10051 0x10060 0x10061 0x10068 0x10069 0x1006a 0x10070 0x10079 0x10080 0x10081 0x10088 0x10089 0x1008b>;
				phandle = <0x3e>;
			};
		};

		dma-controller@11820000 {
			compatible = "renesas,r9a07g044-dmac", "renesas,rz-dmac";
			reg = <0x0 0x11820000 0x0 0x10000 0x0 0x11830000 0x0 0x10000>;
			interrupts = <0x0 0x8d 0x1 0x0 0x7d 0x1 0x0 0x7e 0x1 0x0 0x7f 0x1 0x0 0x80 0x1 0x0 0x81 0x1 0x0 0x82 0x1 0x0 0x83 0x1 0x0 0x84 0x1 0x0 0x85 0x1 0x0 0x86 0x1 0x0 0x87 0x1 0x0 0x88 0x1 0x0 0x89 0x1 0x0 0x8a 0x1 0x0 0x8b 0x1 0x0 0x8c 0x1>;
			interrupt-names = "error", "ch0", "ch1", "ch2", "ch3", "ch4", "ch5", "ch6", "ch7", "ch8", "ch9", "ch10", "ch11", "ch12", "ch13", "ch14", "ch15";
			clocks = <0x4 0x1 0xc 0x4 0x1 0xd>;
			power-domains = <0x4>;
			resets = <0x4 0x11 0x4 0x12>;
			#dma-cells = <0x1>;
			dma-channels = <0x10>;
			phandle = <0x9>;
		};

		gpu@11840000 {
			compatible = "renesas,r9a07g044-mali", "arm,mali-bifrost";
			reg = <0x0 0x11840000 0x0 0x10000>;
			interrupts = <0x0 0x9a 0x4 0x0 0x9b 0x4 0x0 0x99 0x4 0x0 0x9c 0x4>;
			interrupt-names = "job", "mmu", "gpu", "event";
			clocks = <0x4 0x1 0x28 0x4 0x1 0x29 0x4 0x1 0x2a>;
			clock-names = "gpu", "bus", "bus_ace";
			#power-domains = <0x4>;
			resets = <0x4 0x24 0x4 0x25 0x4 0x26>;
			reset-names = "rst", "axi_rst", "ace_rst";
			operating-points-v2 = <0x26>;
			mali-supply = <0x27>;
		};

		interrupt-controller@11900000 {
			compatible = "arm,gic-v3";
			#interrupt-cells = <0x3>;
			#address-cells = <0x0>;
			interrupt-controller;
			reg = <0x0 0x11900000 0x0 0x40000 0x0 0x11940000 0x0 0x60000>;
			interrupts = <0x1 0x9 0x8>;
			phandle = <0x6>;
		};

		mmc@11c00000 {
			compatible = "renesas,sdhi-r9a07g044", "renesas,rcar-gen3-sdhi";
			reg = <0x0 0x11c00000 0x0 0x10000>;
			interrupts = <0x0 0x68 0x4 0x0 0x69 0x4>;
			clocks = <0x4 0x1 0x20 0x4 0x1 0x22 0x4 0x1 0x21 0x4 0x1 0x23>;
			clock-names = "core", "clkh", "cd", "aclk";
			resets = <0x4 0x22>;
			power-domains = <0x4>;
			status = "okay";
			pinctrl-0 = <0x28>;
			pinctrl-1 = <0x28>;
			pinctrl-names = "default", "state_uhs";
			vmmc-supply = <0x1c>;
			vqmmc-supply = <0x1b>;
			bus-width = <0x8>;
			mmc-hs200-1_8v;
			non-removable;
			fixed-emmc-driver-type = <0x1>;
		};

		mmc@11c10000 {
			compatible = "renesas,sdhi-r9a07g044", "renesas,rcar-gen3-sdhi";
			reg = <0x0 0x11c10000 0x0 0x10000>;
			interrupts = <0x0 0x6a 0x4 0x0 0x6b 0x4>;
			clocks = <0x4 0x1 0x24 0x4 0x1 0x26 0x4 0x1 0x25 0x4 0x1 0x27>;
			clock-names = "core", "clkh", "cd", "aclk";
			resets = <0x4 0x23>;
			power-domains = <0x4>;
			status = "okay";
			pinctrl-0 = <0x29>;
			pinctrl-1 = <0x2a>;
			pinctrl-names = "default", "state_uhs";
			vmmc-supply = <0x1c>;
			vqmmc-supply = <0x2b>;
			bus-width = <0x4>;
			sd-uhs-sdr50;
			sd-uhs-sdr104;
			#address-cells = <0x1>;
			#size-cells = <0x0>;
			no-1-8-v;
			no-mmc;
			non-removable;
			keep-power-in-suspend;

			wifi@1 {
				reg = <0x1>;
				compatible = "brcm,bcm4329-fmac";
			};
		};

		ethernet@11c20000 {
			compatible = "renesas,r9a07g044-gbeth", "renesas,rzg2l-gbeth";
			reg = <0x0 0x11c20000 0x0 0x10000>;
			interrupts = <0x0 0x54 0x4 0x0 0x55 0x4 0x0 0x56 0x4>;
			interrupt-names = "mux", "fil", "arp_ns";
			phy-mode = "rgmii-id";
			clocks = <0x4 0x1 0x49 0x4 0x1 0x4a 0x4 0x0 0xe>;
			clock-names = "axi", "chi", "refclk";
			resets = <0x4 0x3b>;
			power-domains = <0x4>;
			#address-cells = <0x1>;
			#size-cells = <0x0>;
			status = "okay";
			pinctrl-0 = <0x2c>;
			pinctrl-names = "default";
			phy-handle = <0x2d>;

			ethernet-phy@7 {
				compatible = "ethernet-phy-id0022.1640", "ethernet-phy-ieee802.3-c22";
				reg = <0x7>;
				rxc-skew-psec = <0x960>;
				txc-skew-psec = <0x960>;
				rxdv-skew-psec = <0x0>;
				txdv-skew-psec = <0x0>;
				rxd0-skew-psec = <0x0>;
				rxd1-skew-psec = <0x0>;
				rxd2-skew-psec = <0x0>;
				rxd3-skew-psec = <0x0>;
				txd0-skew-psec = <0x0>;
				txd1-skew-psec = <0x0>;
				txd2-skew-psec = <0x0>;
				txd3-skew-psec = <0x0>;
				interrupt-parent = <0x10>;
				interrupts = <0x8 0x8>;
			};

			ethernet-phy@4 {
				reg = <0x4>;
				phandle = <0x2d>;
			};

			ethernet-phy@1 {
				reg = <0x1>;
				phandle = <0x2f>;
			};
		};

		ethernet@11c30000 {
			compatible = "renesas,r9a07g044-gbeth", "renesas,rzg2l-gbeth";
			reg = <0x0 0x11c30000 0x0 0x10000>;
			interrupts = <0x0 0x57 0x4 0x0 0x58 0x4 0x0 0x59 0x4>;
			interrupt-names = "mux", "fil", "arp_ns";
			phy-mode = "rgmii-id";
			clocks = <0x4 0x1 0x4b 0x4 0x1 0x4c 0x4 0x0 0xe>;
			clock-names = "axi", "chi", "refclk";
			resets = <0x4 0x3c>;
			power-domains = <0x4>;
			#address-cells = <0x1>;
			#size-cells = <0x0>;
			status = "okay";
			pinctrl-0 = <0x2e>;
			pinctrl-names = "default";
			phy-handle = <0x2f>;

			ethernet-phy@7 {
				compatible = "ethernet-phy-id0022.1640", "ethernet-phy-ieee802.3-c22";
				reg = <0x7>;
				rxc-skew-psec = <0x960>;
				txc-skew-psec = <0x960>;
				rxdv-skew-psec = <0x0>;
				txdv-skew-psec = <0x0>;
				rxd0-skew-psec = <0x0>;
				rxd1-skew-psec = <0x0>;
				rxd2-skew-psec = <0x0>;
				rxd3-skew-psec = <0x0>;
				txd0-skew-psec = <0x0>;
				txd1-skew-psec = <0x0>;
				txd2-skew-psec = <0x0>;
				txd3-skew-psec = <0x0>;
				interrupt-parent = <0x10>;
				interrupts = <0x9 0x8>;
			};
		};

		usbphy-ctrl@11c40000 {
			compatible = "renesas,r9a07g044-usbphy-ctrl", "renesas,rzg2l-usbphy-ctrl";
			reg = <0x0 0x11c40000 0x0 0x10000>;
			clocks = <0x4 0x1 0x48>;
			resets = <0x4 0x3a>;
			power-domains = <0x4>;
			#reset-cells = <0x1>;
			status = "okay";
			phandle = <0x30>;
		};

		usb@11c50000 {
			compatible = "generic-ohci";
			reg = <0x0 0x11c50000 0x0 0x100>;
			interrupts = <0x0 0x5b 0x4>;
			clocks = <0x4 0x1 0x48 0x4 0x1 0x45>;
			resets = <0x30 0x0 0x4 0x37>;
			phys = <0x31 0x1>;
			phy-names = "usb";
			power-domains = <0x4>;
			status = "okay";
			memory-region = <0x32>;
			phandle = <0x34>;
		};

		usb@11c70000 {
			compatible = "generic-ohci";
			reg = <0x0 0x11c70000 0x0 0x100>;
			interrupts = <0x0 0x60 0x4>;
			clocks = <0x4 0x1 0x48 0x4 0x1 0x46>;
			resets = <0x30 0x1 0x4 0x38>;
			phys = <0x33 0x1>;
			phy-names = "usb";
			power-domains = <0x4>;
			status = "okay";
			memory-region = <0x32>;
			phandle = <0x35>;
		};

		usb@11c50100 {
			compatible = "generic-ehci";
			reg = <0x0 0x11c50100 0x0 0x100>;
			interrupts = <0x0 0x5c 0x4>;
			clocks = <0x4 0x1 0x48 0x4 0x1 0x45>;
			resets = <0x30 0x0 0x4 0x37>;
			phys = <0x31 0x2>;
			phy-names = "usb";
			companion = <0x34>;
			power-domains = <0x4>;
			status = "okay";
			memory-region = <0x32>;
		};

		usb@11c70100 {
			compatible = "generic-ehci";
			reg = <0x0 0x11c70100 0x0 0x100>;
			interrupts = <0x0 0x61 0x4>;
			clocks = <0x4 0x1 0x48 0x4 0x1 0x46>;
			resets = <0x30 0x1 0x4 0x38>;
			phys = <0x33 0x2>;
			phy-names = "usb";
			companion = <0x35>;
			power-domains = <0x4>;
			status = "okay";
			memory-region = <0x32>;
		};

		usb-phy@11c50200 {
			compatible = "renesas,usb2-phy-r9a07g044", "renesas,rzg2l-usb2-phy";
			reg = <0x0 0x11c50200 0x0 0x700>;
			interrupts = <0x0 0x5e 0x4>;
			clocks = <0x4 0x1 0x48 0x4 0x1 0x45>;
			resets = <0x30 0x0>;
			#phy-cells = <0x1>;
			power-domains = <0x4>;
			status = "okay";
			phandle = <0x31>;
		};

		usb-phy@11c70200 {
			compatible = "renesas,usb2-phy-r9a07g044", "renesas,rzg2l-usb2-phy";
			reg = <0x0 0x11c70200 0x0 0x700>;
			interrupts = <0x0 0x63 0x4>;
			clocks = <0x4 0x1 0x48 0x4 0x1 0x46>;
			resets = <0x30 0x1>;
			#phy-cells = <0x1>;
			power-domains = <0x4>;
			status = "okay";
			pinctrl-0 = <0x36>;
			pinctrl-names = "default";
			phandle = <0x33>;
		};

		usb@11c60000 {
			compatible = "renesas,usbhs-r9a07g044", "renesas,rza2-usbhs";
			reg = <0x0 0x11c60000 0x0 0x10000>;
			interrupts = <0x0 0x64 0x1 0x0 0x65 0x4 0x0 0x66 0x4 0x0 0x67 0x4>;
			clocks = <0x4 0x1 0x48 0x4 0x1 0x47>;
			resets = <0x30 0x0 0x4 0x39>;
			renesas,buswait = <0x7>;
			phys = <0x31 0x3>;
			phy-names = "usb";
			power-domains = <0x4>;
			status = "disabled";
		};

		watchdog@12800800 {
			compatible = "renesas,r9a07g044-wdt", "renesas,rzg2l-wdt";
			reg = <0x0 0x12800800 0x0 0x400>;
			clocks = <0x4 0x1 0x18 0x4 0x1 0x19>;
			clock-names = "pclk", "oscclk";
			interrupts = <0x0 0x31 0x4 0x0 0x32 0x4>;
			interrupt-names = "wdt", "perrout";
			resets = <0x4 0x1e>;
			power-domains = <0x4>;
			status = "okay";
			timeout-sec = <0x3c>;
		};

		watchdog@12800c00 {
			compatible = "renesas,r9a07g044-wdt", "renesas,rzg2l-wdt";
			reg = <0x0 0x12800c00 0x0 0x400>;
			clocks = <0x4 0x1 0x1a 0x4 0x1 0x1b>;
			clock-names = "pclk", "oscclk";
			interrupts = <0x0 0x33 0x4 0x0 0x34 0x4>;
			interrupt-names = "wdt", "perrout";
			resets = <0x4 0x1f>;
			power-domains = <0x4>;
			status = "okay";
			timeout-sec = <0x3c>;
		};

		watchdog@12800400 {
			compatible = "renesas,r9a07g044-wdt", "renesas,rzg2l-wdt";
			reg = <0x0 0x12800400 0x0 0x400>;
			clocks = <0x4 0x1 0x1c 0x4 0x1 0x1d>;
			clock-names = "pclk", "oscclk";
			interrupts = <0x0 0x35 0x4 0x0 0x36 0x4>;
			interrupt-names = "wdt", "perrout";
			resets = <0x4 0x20>;
			power-domains = <0x4>;
			status = "okay";
			timeout-sec = <0x3c>;
		};

		timer@12801400 {
			compatible = "renesas,r9a07g044-ostm", "renesas,ostm";
			reg = <0x0 0x12801400 0x0 0x400>;
			interrupts = <0x0 0x2f 0x1>;
			clocks = <0x4 0x1 0xf>;
			resets = <0x4 0x15>;
			power-domains = <0x4>;
			status = "okay";
		};

		timer@12801800 {
			compatible = "renesas,r9a07g044-ostm", "renesas,ostm";
			reg = <0x0 0x12801800 0x0 0x400>;
			interrupts = <0x0 0x30 0x1>;
			clocks = <0x4 0x1 0x10>;
			resets = <0x4 0x16>;
			power-domains = <0x4>;
			status = "okay";
		};

		timer@10001200 {
			compatible = "renesas,mtu3";
			reg = <0x0 0x10001200 0x0 0xb00>;
			interrupts = <0x0 0xaa 0x4 0x0 0xab 0x4 0x0 0xac 0x4 0x0 0xad 0x4 0x0 0xae 0x4 0x0 0xaf 0x4 0x0 0xb0 0x4 0x0 0xb1 0x4 0x0 0xb2 0x4 0x0 0xb3 0x4 0x0 0xb4 0x4 0x0 0xb5 0x4 0x0 0xb6 0x4 0x0 0xb7 0x4 0x0 0xb8 0x4 0x0 0xb9 0x4 0x0 0xba 0x4 0x0 0xbb 0x4 0x0 0xbc 0x4 0x0 0xbd 0x4 0x0 0xbe 0x4 0x0 0xbf 0x4 0x0 0xc0 0x4 0x0 0xc1 0x4 0x0 0xc2 0x4 0x0 0xc3 0x4 0x0 0xc4 0x4 0x0 0xc5 0x4 0x0 0xc6 0x4 0x0 0xc7 0x4 0x0 0xc8 0x4 0x0 0xc9 0x4 0x0 0xca 0x4 0x0 0xcb 0x4 0x0 0xcc 0x4 0x0 0xcd 0x4 0x0 0xce 0x4 0x0 0xcf 0x4 0x0 0xd0 0x4 0x0 0xd1 0x4 0x0 0xd2 0x4 0x0 0xd4 0x4 0x0 0xd5 0x4>;
			interrupt-names = "tgi0a", "tci0b", "tgi0c", "tgi0d", "tgi0v", "tgi0e", "tgi0f", "tgi1a", "tgi1b", "tgi1v", "tgi1u", "tgi2a", "tgi2b", "tgi2v", "tgi2u", "tgi3a", "tgi3b", "tgi3c", "tgi3d", "tgi3v", "tgi4a", "tgi4b", "tgi4c", "tgi4d", "tgi4v", "tgi5v", "tgi5u", "tgi5w", "tgi6a", "tgi6b", "tgi6c", "tgi6d", "tgi6v", "tgi7a", "tgi7b", "tgi7c", "tgi7d", "tgi7v", "tgi8a", "tgi8b", "tgi8c", "tgi8d", "tgi8v", "tgi8u";
			clocks = <0x4 0x1 0x11>;
			clock-names = "fck";
			power-domains = <0x4>;
			resets = <0x4 0x17>;
			status = "okay";
		};

		gpt@10048000 {
			compatible = "renesas,gpt-r9a07g044";
			reg = <0x0 0x10048000 0x0 0xa4>;
			#pwm-cells = <0x2>;
			interrupts = <0x0 0xda 0x1 0x0 0xdb 0x1 0x0 0xdc 0x1 0x0 0xdd 0x1 0x0 0xde 0x1 0x0 0xdf 0x1 0x0 0xe0 0x1 0x0 0xe1 0x1 0x0 0xe2 0x1 0x0 0xe3 0x1 0x0 0xe4 0x1 0x0 0xe5 0x1 0x0 0xe6 0x1>;
			interrupt-names = "gtcia", "gtcib", "gtcic", "gtcid", "gtcie", "gtcif", "gtciada", "gtciadb", "gtciv", "gtciu", "gtcih", "gtcil", "gtdei";
			clocks = <0x4 0x1 0x13>;
			power-domains = <0x4>;
			resets = <0x4 0x19>;
			status = "disabled";
		};

		gpt@10048100 {
			compatible = "renesas,gpt-r9a07g044";
			reg = <0x0 0x10048100 0x0 0xa4>;
			#pwm-cells = <0x2>;
			interrupts = <0x0 0xe7 0x1 0x0 0xe8 0x1 0x0 0xe9 0x1 0x0 0xea 0x1 0x0 0xeb 0x1 0x0 0xec 0x1 0x0 0xed 0x1 0x0 0xee 0x1 0x0 0xef 0x1 0x0 0xf0 0x1 0x0 0xf1 0x1 0x0 0xf2 0x1 0x0 0xf3 0x1>;
			interrupt-names = "gtcia", "gtcib", "gtcic", "gtcid", "gtcie", "gtcif", "gtciada", "gtciadb", "gtciv", "gtciu", "gtcih", "gtcil", "gtdei";
			clocks = <0x4 0x1 0x13>;
			power-domains = <0x4>;
			resets = <0x4 0x19>;
			status = "disabled";
		};

		gpt@10048200 {
			compatible = "renesas,gpt-r9a07g044";
			reg = <0x0 0x10048200 0x0 0xa4>;
			#pwm-cells = <0x2>;
			interrupts = <0x0 0xf4 0x1 0x0 0xf5 0x1 0x0 0xf6 0x1 0x0 0xf7 0x1 0x0 0xf8 0x1 0x0 0xf9 0x1 0x0 0xfa 0x1 0x0 0xfb 0x1 0x0 0xfc 0x1 0x0 0xfd 0x1 0x0 0xfe 0x1 0x0 0xff 0x1 0x0 0x100 0x1>;
			interrupt-names = "gtcia", "gtcib", "gtcic", "gtcid", "gtcie", "gtcif", "gtciada", "gtciadb", "gtciv", "gtciu", "gtcih", "gtcil", "gtdei";
			clocks = <0x4 0x1 0x13>;
			power-domains = <0x4>;
			resets = <0x4 0x19>;
			status = "disabled";
		};

		gpt@10048300 {
			compatible = "renesas,gpt-r9a07g044";
			reg = <0x0 0x10048300 0x0 0xa4>;
			#pwm-cells = <0x2>;
			interrupts = <0x0 0x101 0x1 0x0 0x102 0x1 0x0 0x103 0x1 0x0 0x104 0x1 0x0 0x105 0x1 0x0 0x106 0x1 0x0 0x107 0x1 0x0 0x108 0x1 0x0 0x109 0x1 0x0 0x10a 0x1 0x0 0x10b 0x1 0x0 0x10c 0x1 0x0 0x10d 0x1>;
			interrupt-names = "gtcia", "gtcib", "gtcic", "gtcid", "gtcie", "gtcif", "gtciada", "gtciadb", "gtciv", "gtciu", "gtcih", "gtcil", "gtdei";
			clocks = <0x4 0x1 0x13>;
			power-domains = <0x4>;
			resets = <0x4 0x19>;
			status = "disabled";
		};

		gpt@10048400 {
			compatible = "renesas,gpt-r9a07g044";
			reg = <0x0 0x10048400 0x0 0xa4>;
			#pwm-cells = <0x2>;
			interrupts = <0x0 0x10e 0x1 0x0 0x10f 0x1 0x0 0x110 0x1 0x0 0x111 0x1 0x0 0x112 0x1 0x0 0x113 0x1 0x0 0x114 0x1 0x0 0x115 0x1 0x0 0x116 0x1 0x0 0x117 0x1 0x0 0x118 0x1 0x0 0x119 0x1 0x0 0x11a 0x1>;
			interrupt-names = "gtcia", "gtcib", "gtcic", "gtcid", "gtcie", "gtcif", "gtciada", "gtciadb", "gtciv", "gtciu", "gtcih", "gtcil", "gtdei";
			clocks = <0x4 0x1 0x13>;
			power-domains = <0x4>;
			resets = <0x4 0x19>;
			status = "okay";
			pinctrl-0 = <0x37>;
			pinctrl-names = "default";
			channel = "both_AB";
			poeg = <0x38 0x39 0x3a 0x3b>;
		};

		gpt@10048500 {
			compatible = "renesas,gpt-r9a07g044";
			reg = <0x0 0x10048500 0x0 0xa4>;
			#pwm-cells = <0x2>;
			interrupts = <0x0 0x11b 0x1 0x0 0x11c 0x1 0x0 0x11d 0x1 0x0 0x11e 0x1 0x0 0x11f 0x1 0x0 0x120 0x1 0x0 0x121 0x1 0x0 0x122 0x1 0x0 0x123 0x1 0x0 0x124 0x1 0x0 0x125 0x1 0x0 0x126 0x1 0x0 0x127 0x1>;
			interrupt-names = "gtcia", "gtcib", "gtcic", "gtcid", "gtcie", "gtcif", "gtciada", "gtciadb", "gtciv", "gtciu", "gtcih", "gtcil", "gtdei";
			clocks = <0x4 0x1 0x13>;
			power-domains = <0x4>;
			resets = <0x4 0x19>;
			status = "disabled";
		};

		gpt@10048600 {
			compatible = "renesas,gpt-r9a07g044";
			reg = <0x0 0x10048600 0x0 0xa4>;
			#pwm-cells = <0x2>;
			interrupts = <0x0 0x128 0x1 0x0 0x129 0x1 0x0 0x12a 0x1 0x0 0x12b 0x1 0x0 0x12c 0x1 0x0 0x12d 0x1 0x0 0x12e 0x1 0x0 0x12f 0x1 0x0 0x130 0x1 0x0 0x131 0x1 0x0 0x132 0x1 0x0 0x133 0x1 0x0 0x134 0x1>;
			interrupt-names = "gtcia", "gtcib", "gtcic", "gtcid", "gtcie", "gtcif", "gtciada", "gtciadb", "gtciv", "gtciu", "gtcih", "gtcil", "gtdei";
			clocks = <0x4 0x1 0x13>;
			power-domains = <0x4>;
			resets = <0x4 0x19>;
			status = "disabled";
		};

		gpt@10048700 {
			compatible = "renesas,gpt-r9a07g044";
			reg = <0x0 0x10048700 0x0 0xa4>;
			#pwm-cells = <0x2>;
			interrupts = <0x0 0x135 0x1 0x0 0x136 0x1 0x0 0x137 0x1 0x0 0x138 0x1 0x0 0x139 0x1 0x0 0x13a 0x1 0x0 0x13b 0x1 0x0 0x13c 0x1 0x0 0x13d 0x1 0x0 0x13e 0x1 0x0 0x13f 0x1 0x0 0x140 0x1 0x0 0x141 0x1>;
			interrupt-names = "gtcia", "gtcib", "gtcic", "gtcid", "gtcie", "gtcif", "gtciada", "gtciadb", "gtciv", "gtciu", "gtcih", "gtcil", "gtdei";
			clocks = <0x4 0x1 0x13>;
			power-domains = <0x4>;
			resets = <0x4 0x19>;
			status = "disabled";
		};

		vsp@10870000 {
			compatible = "renesas,vsp2";
			reg = <0x0 0x10870000 0x0 0x10000>;
			interrupts = <0x0 0x95 0x4>;
			power-domains = <0x4>;
			renesas,fcp = <0x3c>;
			phandle = <0x3d>;
		};

		fcp@10880000 {
			compatible = "renesas,fcpv";
			reg = <0x0 0x10880000 0x0 0x10000>;
			power-domains = <0x4>;
			phandle = <0x3c>;
		};

		display@10890000 {
			compatible = "renesas,du-rzg2l";
			reg = <0x0 0x10890000 0x0 0x10000>;
			interrupts = <0x0 0x98 0x4>;
			clocks = <0x4 0x1 0x39 0x4 0x1 0x3a 0x4 0x1 0x3b>;
			clock-names = "aclk", "pclk", "dclk";
			resets = <0x4 0x31>;
			vsps = <0x3d 0x0>;
			power-domains = <0x4>;
			status = "okay";
			pinctrl-0 = <0x3e>;
			pinctrl-names = "default";

			ports {
				#address-cells = <0x1>;
				#size-cells = <0x0>;

				port@0 {
					reg = <0x0>;

					endpoint {
						remote-endpoint = <0x3f>;
						phandle = <0x20>;
					};
				};

				port@1 {
					reg = <0x1>;

					endpoint {
						remote-endpoint = <0x40>;
						phandle = <0x41>;
					};
				};
			};
		};

		dsi@10860000 {
			compatible = "renesas,r9a07g044-mipi-dsi";
			reg = <0x0 0x10860000 0x0 0x10000 0x0 0x10850000 0x0 0x10000>;
			clocks = <0x4 0x1 0x33 0x4 0x1 0x34 0x4 0x1 0x35 0x4 0x1 0x36 0x4 0x1 0x37 0x4 0x1 0x38>;
			clock-names = "pllclk", "sysclk", "aclk", "pclk", "vclk", "lpclk";
			resets = <0x4 0x2e 0x4 0x2f 0x4 0x30>;
			reset-names = "cmn_rstb", "areset_n", "preset_n";
			power-domains = <0x4>;
			status = "disabled";

			ports {
				#address-cells = <0x1>;
				#size-cells = <0x0>;

				port@0 {
					reg = <0x0>;

					endpoint {
						remote-endpoint = <0x41>;
						phandle = <0x40>;
					};
				};

				port@1 {
					reg = <0x1>;

					endpoint {
						remote-endpoint = <0x42>;
						data-lanes = <0x1 0x2 0x3 0x4>;
						phandle = <0x1d>;
					};
				};
			};
		};

		video@10830000 {
			compatible = "renesas,cru-r9a07g044";
			reg = <0x0 0x10830000 0x0 0x400>;
			clocks = <0x4 0x1 0x30 0x4 0x1 0x31 0x4 0x1 0x32>;
			clock-names = "vclk", "pclk", "aclk";
			interrupts = <0x0 0xa7 0x4>;
			resets = <0x4 0x2c 0x4 0x2d>;
			reset-names = "presetn", "aresetn";
			power-domains = <0x4>;
			status = "okay";

			ports {
				#address-cells = <0x1>;
				#size-cells = <0x0>;

				port@1 {
					reg = <0x1>;

					endpoint {
						remote-endpoint = <0x43>;
						phandle = <0x44>;
					};
				};
			};
		};

		csi2@10830400 {
			compatible = "renesas,r9a07g044-csi2";
			reg = <0x0 0x10830400 0x0 0xc00>;
			interrupts = <0x0 0xa6 0x4>;
			clocks = <0x4 0x1 0x30 0x4 0x1 0x2f>;
			clock-names = "vclk", "sysclk";
			resets = <0x4 0x2b>;
			reset-names = "cmn_rstb";
			status = "okay";

			ports {
				#address-cells = <0x1>;
				#size-cells = <0x0>;

				port@1 {
					reg = <0x1>;

					endpoint {
						remote-endpoint = <0x44>;
						phandle = <0x43>;
					};
				};

				port {

					endpoint {
						clock-lanes = <0x0>;
						data-lanes = <0x1 0x2>;
						remote-endpoint = <0x45>;
						phandle = <0x19>;
					};
				};
			};
		};
	};

	thermal-zones {

		cpu-thermal {
			polling-delay-passive = <0xfa>;
			polling-delay = <0x3e8>;
			thermal-sensors = <0x46 0x0>;
			sustainable-power = <0x2cd>;

			cooling-maps {

				map0 {
					trip = <0x47>;
					cooling-device = <0x1 0x0 0x2>;
					contribution = <0x400>;
				};
			};

			trips {

				sensor-crit {
					temperature = <0x1e848>;
					hysteresis = <0x3e8>;
					type = "critical";
				};

				trip-point {
					temperature = <0x186a0>;
					hysteresis = <0x3e8>;
					type = "passive";
					phandle = <0x47>;
				};
			};
		};
	};

	timer {
		compatible = "arm,armv8-timer";
		interrupts-extended = <0x6 0x1 0xd 0x308 0x6 0x1 0xe 0x308 0x6 0x1 0xb 0x308 0x6 0x1 0xa 0x308>;
	};

	aliases {
		i2c3 = "/soc/i2c@10058c00";
		ethernet0 = "/soc/ethernet@11c20000";
		ethernet1 = "/soc/ethernet@11c30000";
		serial0 = "/soc/serial@1004b800";
		i2c0 = "/soc/i2c@10058000";
		i2c1 = "/soc/i2c@10058400";
		mmc0 = "/soc/mmc@11c00000";
		mmc1 = "/soc/mmc@11c10000";
	};

	chosen {
		bootargs = "ignore_loglevel rw root=/dev/nfs ip=on";
		stdout-path = "serial0:115200n8";
	};

	memory@48000000 {
		device_type = "memory";
		reg = <0x0 0x48000000 0x0 0x20000000>;
	};

	reserved-memory {
		#address-cells = <0x2>;
		#size-cells = <0x2>;
		ranges;

		linux,cma@58000000 {
			compatible = "shared-dma-pool";
			linux,cma-default;
			reusable;
			reg = <0x0 0x58000000 0x0 0x2000000>;
			phandle = <0x32>;
		};

		linux,multimedia {
			compatible = "shared-dma-pool";
			reusable;
			reg = <0x0 0x5a000000 0x0 0x1000000>;
			phandle = <0x48>;
		};
	};

	mmngr {
		compatible = "renesas,mmngr";
		memory-region = <0x48>;
	};

	mmngrbuf {
		compatible = "renesas,mmngrbuf";
	};

	vspm_if {
		compatible = "renesas,vspm_if";
	};

	regulator0 {
		compatible = "regulator-fixed";
		regulator-name = "fixed-1.8V";
		regulator-min-microvolt = <0x1b7740>;
		regulator-max-microvolt = <0x1b7740>;
		regulator-boot-on;
		regulator-always-on;
		phandle = <0x1b>;
	};

	regulator1 {
		compatible = "regulator-fixed";
		regulator-name = "fixed-3.3V";
		regulator-min-microvolt = <0x325aa0>;
		regulator-max-microvolt = <0x325aa0>;
		regulator-boot-on;
		regulator-always-on;
		phandle = <0x1c>;
	};

	regulator-vdd-core {
		compatible = "regulator-fixed";
		regulator-name = "fixed-1.1V";
		regulator-min-microvolt = <0x10c8e0>;
		regulator-max-microvolt = <0x10c8e0>;
		regulator-boot-on;
		regulator-always-on;
		phandle = <0x27>;
	};

	regulator-vccq-sdhi0 {
		compatible = "regulator-gpio";
		regulator-name = "SDHI0 VccQ";
		regulator-min-microvolt = <0x1b7740>;
		regulator-max-microvolt = <0x325aa0>;
		states = <0x325aa0 0x1 0x1b7740 0x0>;
		regulator-boot-on;
		gpios = <0x10 0x138 0x0>;
		regulator-always-on;
	};

	audio_mclock {
		compatible = "fixed-clock";
		#clock-cells = <0x0>;
		clock-frequency = <0xac4400>;
		phandle = <0x4b>;
	};

	sound {
		compatible = "simple-audio-card";
		simple-audio-card,format = "i2s";
		simple-audio-card,bitclock-master = <0x49>;
		simple-audio-card,frame-master = <0x49>;
		simple-audio-card,mclk-fs = <0x100>;
		simple-audio-card,widgets = "Microphone", "Microphone Jack";
		simple-audio-card,routing = "L2", "Mic Bias", "R2", "Mic Bias", "Mic Bias", "Microphone Jack";

		simple-audio-card,cpu {
			sound-dai = <0x4a>;
			phandle = <0x49>;
		};

		simple-audio-card,codec {
			clocks = <0x4b>;
			sound-dai = <0x4c>;
		};
	};

	regulator-usb0-vbus-otg {
		compatible = "regulator-fixed";
		regulator-name = "USB0_VBUS_OTG";
		regulator-min-microvolt = <0x4c4b40>;
		regulator-max-microvolt = <0x4c4b40>;
	};

	regulator-vccq-sdhi1 {
		compatible = "regulator-gpio";
		regulator-name = "SDHI1 VccQ";
		regulator-min-microvolt = <0x1b7740>;
		regulator-max-microvolt = <0x325aa0>;
		gpios = <0x10 0x139 0x0>;
		gpios-states = <0x1>;
		states = <0x325aa0 0x1 0x1b7740 0x0>;
		phandle = <0x2b>;
	};

	hdmi-out {
		compatible = "hdmi-connector";
		type = [61 00];
		status = "okay";

		port {

			endpoint {
				remote-endpoint = <0x4d>;
				phandle = <0x1e>;
			};
		};
	};

	clk_ext_camera {
		compatible = "fixed-clock";
		#clock-cells = <0x0>;
		clock-frequency = <0x16e3600>;
		phandle = <0x15>;
	};

	1p8v {
		compatible = "regulator-fixed";
		regulator-name = "camera_vdddo";
		regulator-min-microvolt = <0x1b7740>;
		regulator-max-microvolt = <0x1b7740>;
		regulator-always-on;
		phandle = <0x16>;
	};

	2p8v {
		compatible = "regulator-fixed";
		regulator-name = "camera_vdda";
		regulator-min-microvolt = <0x2ab980>;
		regulator-max-microvolt = <0x2ab980>;
		regulator-always-on;
		phandle = <0x17>;
	};

	1p5v {
		compatible = "regulator-fixed";
		regulator-name = "camera_vddd";
		regulator-min-microvolt = <0x16e360>;
		regulator-max-microvolt = <0x16e360>;
		regulator-always-on;
		phandle = <0x18>;
	};

	sound_card {
		compatible = "audio-graph-card";
		dais = <0x4e>;
	};
};
